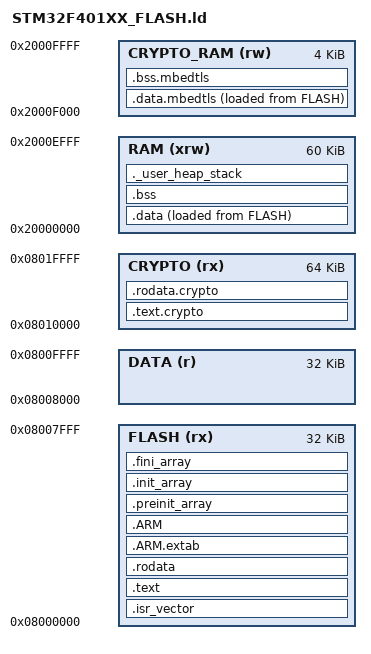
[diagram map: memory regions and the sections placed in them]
/*
******************************************************************************
**

**  File        : LinkerScript.ld
**
**  Author		: STM32CubeMX
**
**  Abstract    : Linker script for STM32F401RCTx series
**                256Kbytes FLASH and 64Kbytes RAM
**
**                Set heap size, stack size and stack location according
**                to application requirements.
**
**                Set memory bank area and size if external memory is used.
**
**  Target      : STMicroelectronics STM32
**
**  Distribution: The file is distributed “as is,” without any warranty
**                of any kind.
**
*****************************************************************************
** @attention
**
** <h2><center>&copy; COPYRIGHT(c) 2025 STMicroelectronics</center></h2>
**
** Redistribution and use in source and binary forms, with or without modification,
** are permitted provided that the following conditions are met:
**   1. Redistributions of source code must retain the above copyright notice,
**      this list of conditions and the following disclaimer.
**   2. Redistributions in binary form must reproduce the above copyright notice,
**      this list of conditions and the following disclaimer in the documentation
**      and/or other materials provided with the distribution.
**   3. Neither the name of STMicroelectronics nor the names of its contributors
**      may be used to endorse or promote products derived from this software
**      without specific prior written permission.
**
** THIS SOFTWARE IS PROVIDED BY THE COPYRIGHT HOLDERS AND CONTRIBUTORS "AS IS"
** AND ANY EXPRESS OR IMPLIED WARRANTIES, INCLUDING, BUT NOT LIMITED TO, THE
** IMPLIED WARRANTIES OF MERCHANTABILITY AND FITNESS FOR A PARTICULAR PURPOSE ARE
** DISCLAIMED. IN NO EVENT SHALL THE COPYRIGHT HOLDER OR CONTRIBUTORS BE LIABLE
** FOR ANY DIRECT, INDIRECT, INCIDENTAL, SPECIAL, EXEMPLARY, OR CONSEQUENTIAL
** DAMAGES (INCLUDING, BUT NOT LIMITED TO, PROCUREMENT OF SUBSTITUTE GOODS OR
** SERVICES; LOSS OF USE, DATA, OR PROFITS; OR BUSINESS INTERRUPTION) HOWEVER
** CAUSED AND ON ANY THEORY OF LIABILITY, WHETHER IN CONTRACT, STRICT LIABILITY,
** OR TORT (INCLUDING NEGLIGENCE OR OTHERWISE) ARISING IN ANY WAY OUT OF THE USE
** OF THIS SOFTWARE, EVEN IF ADVISED OF THE POSSIBILITY OF SUCH DAMAGE.
**
*****************************************************************************
*/

/* Entry Point */
ENTRY(Reset_Handler)

/* Highest address of the user mode stack */
_estack = ORIGIN(RAM) + LENGTH(RAM);    /* end of RAM */
/* Generate a link error if heap and stack don't fit into RAM */
_Min_Heap_Size = 0x400;      /* required amount of heap  */
_Min_Stack_Size = 0x800; /* required amount of stack */

/* Specify the memory areas */
MEMORY
{
RAM (xrw)      : ORIGIN = 0x20000000, LENGTH = 60K
CRYPTO_RAM (rw)      : ORIGIN = 0x2000F000, LENGTH = 4K
FLASH (rx)     : ORIGIN = 0x8000000, LENGTH = 32K
DATA   (r)     : ORIGIN = 0x08008000, LENGTH = 32K
CRYPTO (rx)    : ORIGIN = 0x08010000, LENGTH = 64K
}

/* Define output sections */
SECTIONS
{
  /* The startup code goes first into FLASH */
  .isr_vector :
  {
    . = ALIGN(4);
    KEEP(*(.isr_vector)) /* Startup code */
    . = ALIGN(4);
  } >FLASH

  /* The program code and other data goes into FLASH */
  .text :
  {
    . = ALIGN(4);
    *(EXCLUDE_FILE(*libmbedTLS.a:*) .text)
    *(EXCLUDE_FILE(*libmbedTLS.a:*) .text*)
    *(.glue_7)         /* glue arm to thumb code */
    *(.glue_7t)        /* glue thumb to arm code */
    *(.eh_frame)

    KEEP (*(.init))
    KEEP (*(.fini))

    . = ALIGN(4);
    _etext = .;        /* define a global symbols at end of code */
  } >FLASH

  .text.crypto :
  {
    . = ALIGN(4);
    KEEP(*libmbedTLS.a:*(.text*))
    *libmbedTLS.a:*(.text*)
    . = ALIGN(4);
  } > CRYPTO

  .rodata.crypto :
  {
    . = ALIGN(4);
    *libmbedTLS.a:*(.rodata)
    *libmbedTLS.a:*(.rodata*)
    . = ALIGN(4);
  } >CRYPTO

  /* Constant data goes into FLASH */
  .rodata :
  {
    . = ALIGN(4);
    *(EXCLUDE_FILE(*libmbedTLS.a:*) .rodata)
    *(EXCLUDE_FILE(*libmbedTLS.a:*) .rodata*)
    . = ALIGN(4);
  } >FLASH

  .ARM.extab (READONLY) : /* The "READONLY" keyword is only supported in GCC11 and later, remove it if using GCC10 or earlier. */
  {
    . = ALIGN(4);
    *(.ARM.extab* .gnu.linkonce.armextab.*)
    . = ALIGN(4);
  } >FLASH

  .ARM (READONLY) : /* The "READONLY" keyword is only supported in GCC11 and later, remove it if using GCC10 or earlier. */
  {
    . = ALIGN(4);
    __exidx_start = .;
    *(.ARM.exidx*)
    __exidx_end = .;
    . = ALIGN(4);
  } >FLASH

  .preinit_array (READONLY) : /* The "READONLY" keyword is only supported in GCC11 and later, remove it if using GCC10 or earlier. */
  {
    . = ALIGN(4);
    PROVIDE_HIDDEN (__preinit_array_start = .);
    KEEP (*(.preinit_array*))
    PROVIDE_HIDDEN (__preinit_array_end = .);
    . = ALIGN(4);
  } >FLASH

  .init_array (READONLY) : /* The "READONLY" keyword is only supported in GCC11 and later, remove it if using GCC10 or earlier. */
  {
    . = ALIGN(4);
    PROVIDE_HIDDEN (__init_array_start = .);
    KEEP (*(SORT(.init_array.*)))
    KEEP (*(.init_array*))
    PROVIDE_HIDDEN (__init_array_end = .);
    . = ALIGN(4);
  } >FLASH

  .fini_array (READONLY) : /* The "READONLY" keyword is only supported in GCC11 and later, remove it if using GCC10 or earlier. */
  {
    . = ALIGN(4);
    PROVIDE_HIDDEN (__fini_array_start = .);
    KEEP (*(SORT(.fini_array.*)))
    KEEP (*(.fini_array*))
    PROVIDE_HIDDEN (__fini_array_end = .);
    . = ALIGN(4);
  } >FLASH

  /* used by the startup to initialize data */
  _sidata = LOADADDR(.data);

  /* Initialized data sections goes into RAM, load LMA copy after code */
  .data :
  {
    . = ALIGN(4);
    _sdata = .;        /* create a global symbol at data start */
    *(EXCLUDE_FILE(*libmbedTLS.a:*) .data)
    *(EXCLUDE_FILE(*libmbedTLS.a:*) .data*)
    *(.RamFunc)        /* .RamFunc sections */
    *(.RamFunc*)       /* .RamFunc* sections */

    . = ALIGN(4);
    _edata = .;        /* define a global symbol at data end */
  } >RAM AT> FLASH


  /* Uninitialized data section */
  . = ALIGN(4);
  .bss :
  {
    /* This is used by the startup in order to initialize the .bss secion */
    _sbss = .;         /* define a global symbol at bss start */
    __bss_start__ = _sbss;
    *(EXCLUDE_FILE(*libmbedTLS.a:*) .bss)
    *(EXCLUDE_FILE(*libmbedTLS.a:*) .bss*)
    *(COMMON)

    . = ALIGN(4);
    _ebss = .;         /* define a global symbol at bss end */
    __bss_end__ = _ebss;
  } >RAM

  /* User_heap_stack section, used to check that there is enough RAM left */
  ._user_heap_stack :
  {
    . = ALIGN(8);
    PROVIDE ( end = . );
    PROVIDE ( _end = . );
    . = . + _Min_Heap_Size;
    . = . + _Min_Stack_Size;
    . = ALIGN(8);
  } >RAM

  _crypto_sidata = LOADADDR(.data.mbedtls);
  .data.mbedtls : 
  {
    _crypto_sdata = .;
    *libmbedTLS.a:*(.data*)
    _crypto_edata = .;
  } > CRYPTO_RAM AT > FLASH

  .bss.mbedtls (NOLOAD) : ALIGN(4)
  {
    _crypto_sbss = .;
    *libmbedTLS.a:*(.bss*)
    _crypto_ebss = .;
  } > CRYPTO_RAM

  /* Remove information from the standard libraries */
  /DISCARD/ :
  {
    libc.a ( * )
    libm.a ( * )
    libgcc.a ( * )
  }

}


